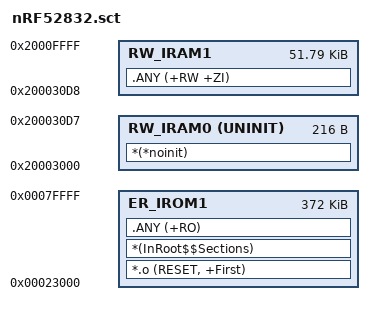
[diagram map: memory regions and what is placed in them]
#! armcc -E

#if !defined(MBED_APP_START)
  #define MBED_APP_START 0x23000
#endif

#if !defined(MBED_APP_SIZE)
  #define MBED_APP_SIZE 0x5D000
#endif

LR_IROM1 MBED_APP_START MBED_APP_SIZE {
  ER_IROM1 MBED_APP_START MBED_APP_SIZE {
   *.o (RESET, +First)
   *(InRoot$$Sections)
   .ANY (+RO)
  }
  RW_IRAM0 0x20003000 UNINIT 0x000000D8 { ;no init section
        *(*noinit)
  }
  RW_IRAM1 0x200030D8 0x0000CF28 {
   .ANY (+RW +ZI)
  }
}
